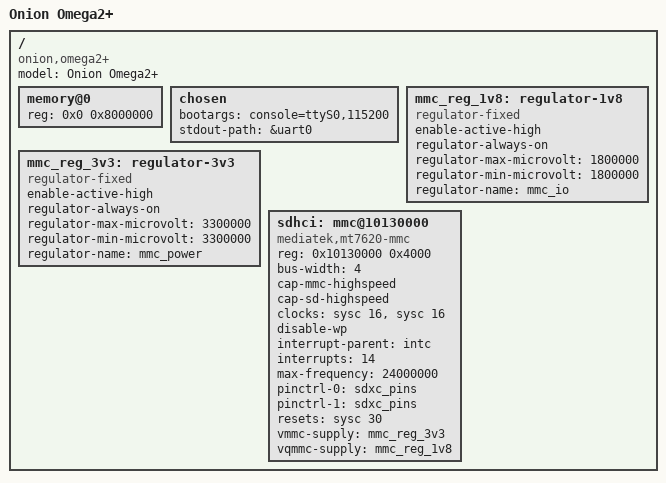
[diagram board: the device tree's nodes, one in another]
/dts-v1/;

#include "mt7628a.dtsi"

/ {
	compatible = "onion,omega2+", "ralink,mt7688a-soc", "ralink,mt7628a-soc";
	model = "Onion Omega2+";

	memory@0 {
		device_type = "memory";
		reg = <0x0 0x8000000>;
	};

	chosen {
		bootargs = "console=ttyS0,115200";
		stdout-path = &uart0;
	};

	mmc_reg_1v8: regulator-1v8 {
		compatible = "regulator-fixed";

		enable-active-high;

		regulator-always-on;
		regulator-max-microvolt = <1800000>;
		regulator-min-microvolt = <1800000>;
		regulator-name = "mmc_io";
	};

	mmc_reg_3v3: regulator-3v3 {
		compatible = "regulator-fixed";

		enable-active-high;

		regulator-always-on;
		regulator-max-microvolt = <3300000>;
		regulator-min-microvolt = <3300000>;
		regulator-name = "mmc_power";
	};

	sdhci: mmc@10130000 {
		compatible = "mediatek,mt7620-mmc", "ralink,mt7620-sdhci";
		reg = <0x10130000 0x4000>;

		bus-width = <4>;

		cap-mmc-highspeed;
		cap-sd-highspeed;

		clocks = <&sysc 16>, <&sysc 16>;
		clock-names = "source", "hclk";

		disable-wp;

		interrupt-parent = <&intc>;
		interrupts = <14>;

		max-frequency = <24000000>;

		pinctrl-names = "default", "state_uhs";
		pinctrl-0 = <&sdxc_pins>;
		pinctrl-1 = <&sdxc_pins>;

		resets = <&sysc 30>;
		reset-names = "hrst";

		vmmc-supply = <&mmc_reg_3v3>;
		vqmmc-supply = <&mmc_reg_1v8>;

		status = "okay";
	};
};
